VERSION "1.0"

NS_ :

BS_:

BU_: VCU ADAS GNSS

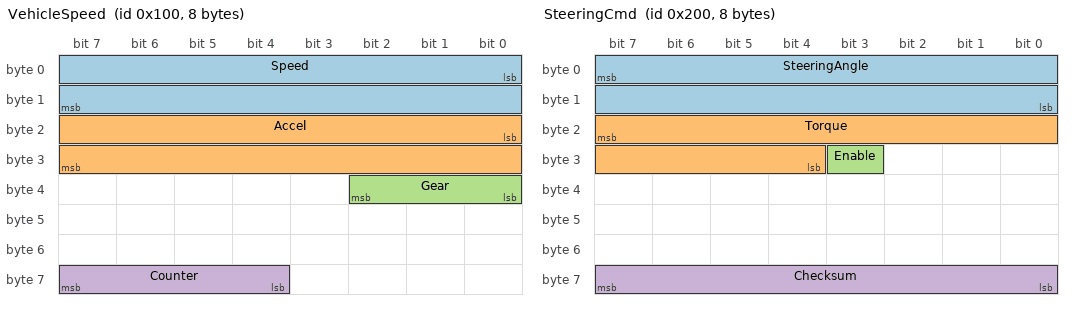
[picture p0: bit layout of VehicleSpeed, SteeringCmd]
BO_ 256 VehicleSpeed: 8 VCU
 SG_ Speed : 0|16@1+ (0.01,0) [0|655.35] "km/h" ADAS
 SG_ Accel : 16|16@1- (0.001,-2) [-34|30] "m/s^2" ADAS
 SG_ Gear : 32|3@1+ (1,0) [0|7] "" ADAS
 SG_ Counter : 60|4@1+ (1,0) [0|15] "" ADAS

BO_ 512 SteeringCmd: 8 ADAS
 SG_ SteeringAngle : 7|16@0- (0.1,0) [-780|780] "deg" VCU
 SG_ Torque : 23|12@0+ (0.01,-20) [-20|20.95] "Nm" VCU
 SG_ Enable : 27|1@0+ (1,0) [0|1] "" VCU
 SG_ Checksum : 63|8@0+ (1,0) [0|255] "" VCU

BO_ 2148532224 Diagnostic: 8 ADAS
 SG_ Mode M : 0|8@1+ (1,0) [0|0] "" VCU
 SG_ Temperature m1 : 8|16@1- (0.1,0) [0|0] "degC" VCU
 SG_ Voltage m2 : 8|16@1+ (0.001,0) [0|0] "V" VCU
 SG_ ErrorCode m2 : 24|8@1+ (1,0) [0|0] "" VCU

BO_ 768 ImuData: 8 GNSS
 SG_ YawRate : 0|32@1- (1,0) [0|0] "rad/s" ADAS
 SG_ LatAccel : 32|32@1- (1,0) [0|0] "m/s^2" ADAS

BO_ 1024 RadarObjects: 64 ADAS
 SG_ ObjectCount : 0|8@1+ (1,0) [0|64] "" VCU
 SG_ Distance : 8|16@1+ (0.01,0) [0|655.35] "m" VCU
 SG_ Tail : 504|8@1+ (1,0) [0|255] "" VCU

CM_ BO_ 256 "Vehicle speed from the VCU";
CM_ SG_ 256 Speed "Vehicle speed over ground";
BA_DEF_ BO_  "GenMsgCycleTime" INT 0 10000;
BA_DEF_ SG_  "GenSigStartValue" FLOAT -1e10 1e10;
BA_DEF_ BO_  "VFrameFormat" ENUM  "StandardCAN","ExtendedCAN","reserved","reserved","reserved","reserved","reserved","reserved","reserved","reserved","reserved","reserved","reserved","reserved","StandardCAN_FD","ExtendedCAN_FD";
BA_DEF_DEF_  "GenMsgCycleTime" 0;
BA_DEF_DEF_  "GenSigStartValue" 0;
BA_DEF_DEF_  "VFrameFormat" "StandardCAN";
BA_ "GenMsgCycleTime" BO_ 256 10;
BA_ "GenMsgCycleTime" BO_ 512 20;
BA_ "VFrameFormat" BO_ 1024 14;
BA_ "GenSigStartValue" SG_ 256 Gear 3;
VAL_ 256 Gear 0 "P" 1 "R" 2 "N" 3 "D" ;
VAL_ 2148532224 Mode 1 "Thermal" 2 "Power" ;
SIG_VALTYPE_ 768 YawRate : 1;
SIG_VALTYPE_ 768 LatAccel : 1;
